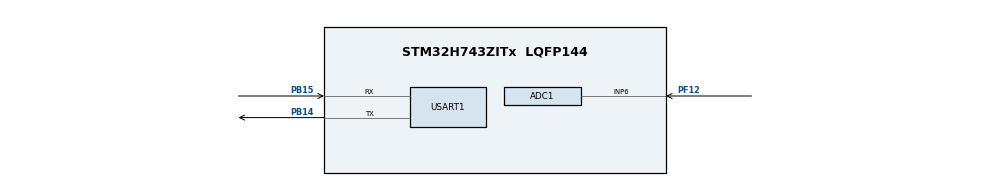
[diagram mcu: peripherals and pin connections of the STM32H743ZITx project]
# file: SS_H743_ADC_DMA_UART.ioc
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ADC1.Channel-0\#ChannelRegularConversion=ADC_CHANNEL_6
ADC1.ClockPrescaler=ADC_CLOCK_ASYNC_DIV2
ADC1.ContinuousConvMode=ENABLE
ADC1.ConversionDataManagement=ADC_CONVERSIONDATA_DMA_CIRCULAR
ADC1.NbrOfConversionFlag=1
ADC1.OffsetNumber-0\#ChannelRegularConversion=ADC_OFFSET_NONE
ADC1.Rank-0\#ChannelRegularConversion=1
ADC1.SamplingTime-0\#ChannelRegularConversion=ADC_SAMPLETIME_64CYCLES_5
ADC1.master=1
Dma.ADC1.0.Direction=DMA_PERIPH_TO_MEMORY
Dma.ADC1.0.EventEnable=DISABLE
Dma.ADC1.0.FIFOMode=DMA_FIFOMODE_DISABLE
Dma.ADC1.0.Instance=DMA1_Stream6
Dma.ADC1.0.MemDataAlignment=DMA_MDATAALIGN_WORD
Dma.ADC1.0.MemInc=DMA_MINC_ENABLE
Dma.ADC1.0.Mode=DMA_NORMAL
Dma.ADC1.0.PeriphDataAlignment=DMA_PDATAALIGN_WORD
Dma.ADC1.0.PeriphInc=DMA_PINC_DISABLE
Dma.ADC1.0.Polarity=HAL_DMAMUX_REQ_GEN_RISING
Dma.ADC1.0.Priority=DMA_PRIORITY_LOW
Dma.ADC1.0.RequestNumber=1
Dma.ADC1.0.SignalID=NONE
Dma.ADC1.0.SyncEnable=DISABLE
Dma.ADC1.0.SyncPolarity=HAL_DMAMUX_SYNC_NO_EVENT
Dma.ADC1.0.SyncRequestNumber=1
Dma.ADC1.0.SyncSignalID=NONE
Dma.Request0=ADC1
Mcu.Family=STM32H7
Mcu.Name=STM32H743ZITx
Mcu.Package=LQFP144
NVIC.DMA1_Stream6_IRQn=true\:0\:0\:false\:false\:true\:false\:true
NVIC.PriorityGroup=NVIC_PRIORITYGROUP_4
PB14.Mode=Asynchronous
PB14.Signal=USART1_TX
PB15.Mode=Asynchronous
PB15.Signal=USART1_RX
PF12.Mode=IN6-Single-Ended
PF12.Signal=ADC1_INP6
ProjectManager.HeapSize=0x200
ProjectManager.StackSize=0x400
ProjectManager.TargetToolchain=MDK-ARM V5.27
RCC.ADCFreq_Value=32000000
RCC.APB1Freq_Value=64000000
RCC.APB2Freq_Value=64000000
RCC.APB3Freq_Value=64000000
RCC.APB4Freq_Value=64000000
RCC.CortexFreq_Value=64000000
RCC.DIVM2=4
RCC.DIVN2=10
RCC.DIVP1=32
RCC.DIVP2=5
RCC.HCLKFreq_Value=64000000
RCC.PLL2FRACN=0
RCC.SYSCLKFreq_VALUE=64000000
RCC.USBFreq_Value=129000000
USART1.VirtualMode-Asynchronous=VM_ASYNC
board=custom

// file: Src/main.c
/* USER CODE BEGIN Header */
/**
  ******************************************************************************
  * @file           : main.c
  * @brief          : Main program body
  ******************************************************************************
  * @attention
  *
  * <h2><center>&copy; Copyright (c) 2020 STMicroelectronics.
  * All rights reserved.</center></h2>
  *
  * This software component is licensed by ST under BSD 3-Clause license,
  * the "License"; You may not use this file except in compliance with the
  * License. You may obtain a copy of the License at:
  *                        opensource.org/licenses/BSD-3-Clause
  *
  ******************************************************************************
  */
/* USER CODE END Header */

#include "main.h"
#include "adc.h"
#include "dma.h"
#include "usart.h"
#include "gpio.h"

/* USER CODE BEGIN Includes */
#include "arm_math.h"
#include "stdio.h"
#define FFT_LENGTH		1024 		//FFT长度，默认是1024点FFT

float fft_inputbuf[FFT_LENGTH*2];	//FFT输入数组
float fft_outputbuf[FFT_LENGTH];	//FFT输出数组

/* USER CODE END Includes */

void SystemClock_Config(void);

int main(void)
{
  /* USER CODE BEGIN 1 */
//	arm_cfft_radix4_instance_f32 scfft;
	int i ;
	uint32_t rx[3] = {5} ;
//	arm_cfft_radix4_init_f32(&scfft,1024,0,1);//初始化scfft结构体，设定FFT相关参数
//
//	for(i=0;i<FFT_LENGTH;i++)//生成信号序列
//			{
//				 fft_inputbuf[2*i]=100+
//				                   10*arm_sin_f32(2*PI*i/FFT_LENGTH)+
//								   30*arm_sin_f32(2*PI*i*4/FFT_LENGTH)+
//				                   50*arm_cos_f32(2*PI*i*8/FFT_LENGTH);	//生成输入信号实部
//				 fft_inputbuf[2*i+1]=0;//虚部全部为0
//			}
//			arm_cfft_radix4_f32(&scfft,fft_inputbuf);	//FFT计算（基4）
//			arm_cmplx_mag_f32(fft_inputbuf,fft_outputbuf,FFT_LENGTH);	//把运算结果复数求模得幅值
  /* USER CODE END 1 */

  /* MCU Configuration--------------------------------------------------------*/

  /* Reset of all peripherals, Initializes the Flash interface and the Systick. */
  HAL_Init();

  /* Configure the system clock */
  SystemClock_Config();

  /* Initialize all configured peripherals */
  MX_GPIO_Init();
  MX_DMA_Init();
  MX_ADC1_Init();
  MX_USART1_UART_Init();

  /* Infinite loop */
  /* USER CODE BEGIN WHILE */
  while (1)
		{
		HAL_ADC_Start_DMA(&hadc1,rx,3) ;
		HAL_Delay(1000);
		HAL_ADC_Stop_DMA(&hadc1);
		for(i=0;i<3;i++){
			printf("%d, %d\r\n",i+1,rx[i]);
		}
		printf("\r\n---1\r\n\r\n\r\n");
		HAL_Delay(1000);
    /* USER CODE END WHILE */

  }
}

void SystemClock_Config(void)
{
  RCC_OscInitTypeDef RCC_OscInitStruct = {0};
  RCC_ClkInitTypeDef RCC_ClkInitStruct = {0};
  RCC_PeriphCLKInitTypeDef PeriphClkInitStruct = {0};

  /** Supply configuration update enable
  */
  HAL_PWREx_ConfigSupply(PWR_LDO_SUPPLY);
  /** Configure the main internal regulator output voltage
  */
  __HAL_PWR_VOLTAGESCALING_CONFIG(PWR_REGULATOR_VOLTAGE_SCALE3);

  while(!__HAL_PWR_GET_FLAG(PWR_FLAG_VOSRDY)) {}
  /** Macro to configure the PLL clock source
  */
  __HAL_RCC_PLL_PLLSOURCE_CONFIG(RCC_PLLSOURCE_HSI);
  /** Initializes the CPU, AHB and APB busses clocks
  */
  RCC_OscInitStruct.OscillatorType = RCC_OSCILLATORTYPE_HSI;
  RCC_OscInitStruct.HSIState = RCC_HSI_DIV1;
  RCC_OscInitStruct.HSICalibrationValue = RCC_HSICALIBRATION_DEFAULT;
  RCC_OscInitStruct.PLL.PLLState = RCC_PLL_NONE;
  RCC_OscInitStruct.PLL.PLLSource = RCC_PLLSOURCE_HSI;
  if (HAL_RCC_OscConfig(&RCC_OscInitStruct) != HAL_OK)
  {
    Error_Handler();
  }
  /** Initializes the CPU, AHB and APB busses clocks
  */
  RCC_ClkInitStruct.ClockType = RCC_CLOCKTYPE_HCLK|RCC_CLOCKTYPE_SYSCLK
                              |RCC_CLOCKTYPE_PCLK1|RCC_CLOCKTYPE_PCLK2
                              |RCC_CLOCKTYPE_D3PCLK1|RCC_CLOCKTYPE_D1PCLK1;
  RCC_ClkInitStruct.SYSCLKSource = RCC_SYSCLKSOURCE_HSI;
  RCC_ClkInitStruct.SYSCLKDivider = RCC_SYSCLK_DIV1;
  RCC_ClkInitStruct.AHBCLKDivider = RCC_HCLK_DIV1;
  RCC_ClkInitStruct.APB3CLKDivider = RCC_APB3_DIV1;
  RCC_ClkInitStruct.APB1CLKDivider = RCC_APB1_DIV1;
  RCC_ClkInitStruct.APB2CLKDivider = RCC_APB2_DIV1;
  RCC_ClkInitStruct.APB4CLKDivider = RCC_APB4_DIV1;

  if (HAL_RCC_ClockConfig(&RCC_ClkInitStruct, FLASH_LATENCY_0) != HAL_OK)
  {
    Error_Handler();
  }
  PeriphClkInitStruct.PeriphClockSelection = RCC_PERIPHCLK_USART1|RCC_PERIPHCLK_ADC;
  PeriphClkInitStruct.PLL2.PLL2M = 4;
  PeriphClkInitStruct.PLL2.PLL2N = 10;
  PeriphClkInitStruct.PLL2.PLL2P = 5;
  PeriphClkInitStruct.PLL2.PLL2Q = 2;
  PeriphClkInitStruct.PLL2.PLL2R = 2;
  PeriphClkInitStruct.PLL2.PLL2RGE = RCC_PLL2VCIRANGE_3;
  PeriphClkInitStruct.PLL2.PLL2VCOSEL = RCC_PLL2VCOMEDIUM;
  PeriphClkInitStruct.PLL2.PLL2FRACN = 0;
  PeriphClkInitStruct.Usart16ClockSelection = RCC_USART16CLKSOURCE_D2PCLK2;
  PeriphClkInitStruct.AdcClockSelection = RCC_ADCCLKSOURCE_PLL2;
  if (HAL_RCCEx_PeriphCLKConfig(&PeriphClkInitStruct) != HAL_OK)
  {
    Error_Handler();
  }
}

void Error_Handler(void)
{
}

/************************ (C) COPYRIGHT STMicroelectronics *****END OF FILE****/
